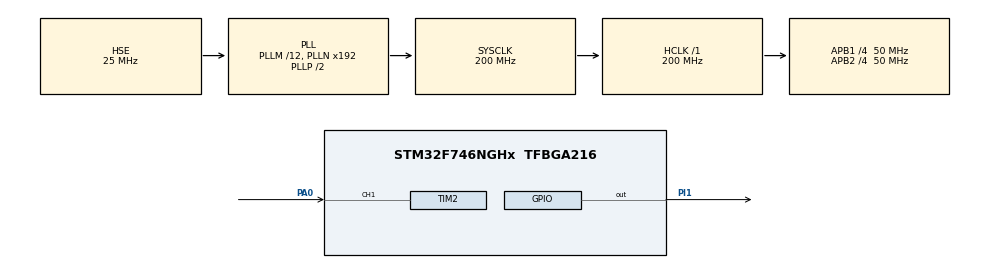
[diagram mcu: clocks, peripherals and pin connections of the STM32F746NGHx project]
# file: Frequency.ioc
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Mcu.Family=STM32F7
Mcu.Name=STM32F746NGHx
Mcu.Package=TFBGA216
NVIC.PVD_IRQn=true\:0\:0\:false\:false\:true\:true\:true
NVIC.PriorityGroup=NVIC_PRIORITYGROUP_4
NVIC.TIM2_IRQn=true\:0\:0\:false\:false\:true\:true\:true
PA0/WKUP.Signal=S_TIM2_CH1_ETR
PA13.Mode=Serial_Wire
PA13.Signal=SYS_JTMS-SWDIO
PA14.Mode=Serial_Wire
PA14.Signal=SYS_JTCK-SWCLK
PC14/OSC32_IN.Mode=LSE-External-Oscillator
PC14/OSC32_IN.Signal=RCC_OSC32_IN
PC15/OSC32_OUT.Mode=LSE-External-Oscillator
PC15/OSC32_OUT.Signal=RCC_OSC32_OUT
PH0/OSC_IN.Mode=HSE-External-Oscillator
PH0/OSC_IN.Signal=RCC_OSC_IN
PH1/OSC_OUT.Mode=HSE-External-Oscillator
PH1/OSC_OUT.Signal=RCC_OSC_OUT
PI1.Signal=GPIO_Output
ProjectManager.HeapSize=0x200
ProjectManager.StackSize=0x400
ProjectManager.TargetToolchain=STM32CubeIDE
RCC.AHBFreq_Value=200000000
RCC.APB1CLKDivider=RCC_HCLK_DIV4
RCC.APB1Freq_Value=50000000
RCC.APB1TimFreq_Value=100000000
RCC.APB2CLKDivider=RCC_HCLK_DIV4
RCC.APB2Freq_Value=50000000
RCC.APB2TimFreq_Value=100000000
RCC.CortexFreq_Value=200000000
RCC.HCLKFreq_Value=200000000
RCC.HSE_VALUE=25000000
RCC.HSI_VALUE=16000000
RCC.PLL48CLockSelection=RCC_CLK48SOURCE_PLLSAIP
RCC.PLLI2SN=100
RCC.PLLM=12
RCC.PLLQ=9
RCC.PLLSAIN=384
RCC.PLLSAIP=RCC_PLLSAIP_DIV8
RCC.PLLSAIR=5
RCC.PLLSAIRDiv=RCC_PLLSAIDIVR_8
RCC.PLLSourceVirtual=RCC_PLLSOURCE_HSE
RCC.SDMMCClockSelection=RCC_SDMMC1CLKSOURCE_CLK48
RCC.SYSCLKFreq_VALUE=200000000
RCC.SYSCLKSource=RCC_SYSCLKSOURCE_PLLCLK
RCC.USBFreq_Value=100000000
RCC.VCOOutputFreq_Value=400000000
SH.S_TIM2_CH1_ETR.0=TIM2_CH1,Input_Capture1_from_TI1
TIM2.Channel-Input_Capture1_from_TI1=TIM_CHANNEL_1
TIM2.ICFilter_CH1=15
TIM2.ICPrescaler-Input_Capture1_from_TI1=TIM_ICPSC_DIV1
TIM2.Prescaler=10-1
VP_CRC_VS_CRC.Mode=CRC_Activate
VP_DMA2D_VS_DMA2D.Mode=DMA2D_Activate
VP_RTC_VS_RTC_Activate.Mode=RTC_Enabled
board=STM32F746G-DISCO

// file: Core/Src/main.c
/* USER CODE BEGIN Header */
/**
  ******************************************************************************
  * @file           : main.c
  * @brief          : Main program body
  ******************************************************************************
  * @attention
  *
  * <h2><center>&copy; Copyright (c) 2021 STMicroelectronics.
  * All rights reserved.</center></h2>
  *
  * This software component is licensed by ST under Ultimate Liberty license
  * SLA0044, the "License"; You may not use this file except in compliance with
  * the License. You may obtain a copy of the License at:
  *                             www.st.com/SLA0044
  *
  ******************************************************************************
  */
/* USER CODE END Header */
#include "main.h"

CRC_HandleTypeDef hcrc;

DMA2D_HandleTypeDef hdma2d;

RTC_HandleTypeDef hrtc;

TIM_HandleTypeDef htim2;

/* USER CODE BEGIN PV */
float IC_Value1 = 0;
float IC_Value2 = 0;
float Difference = 0;
float Frequency = 0;
uint8_t Is_First_Captured = 0;

uint8_t counter_1_1;
uint8_t counter_1_2;
uint8_t counter_1_3;
uint8_t counter_1_4;

uint32_t counter1value_int=0;

//uint32_t counter;
uint32_t read;

uint32_t fr_apb1 = 0;

/* USER CODE END PV */

void SystemClock_Config(void);
static void MX_GPIO_Init(void);
static void MX_TIM2_Init(void);
static void MX_RTC_Init(void);
static void MX_CRC_Init(void);
static void MX_DMA2D_Init(void);

/* USER CODE BEGIN 0 */

TS_StateTypeDef  ts;

char tCounter[20];
char xTouchStr[10];
char freq[10];

/* USER CODE END 0 */

int main(void)
{

  /* MCU Configuration--------------------------------------------------------*/

  /* Reset of all peripherals, Initializes the Flash interface and the Systick. */
  HAL_Init();

  /* Configure the system clock */
  SystemClock_Config();

  /* Initialize all configured peripherals */
  MX_GPIO_Init();
  MX_TIM2_Init();
  MX_RTC_Init();
  MX_CRC_Init();
  MX_DMA2D_Init();
  /* USER CODE BEGIN 2 */

  HAL_TIM_IC_Start_IT(&htim2, TIM_CHANNEL_1);

  HAL_Delay(100);

  BSP_SDRAM_Init(); /* Initializes the SDRAM device */

  BSP_TS_Init(480, 272);
  BSP_LCD_Init();
  BSP_LCD_LayerDefaultInit(0, LCD_FB_START_ADDRESS);
  BSP_LCD_DisplayOn();
  BSP_LCD_SelectLayer(0);
  BSP_LCD_Clear(LCD_COLOR_BLUE);

  HAL_Delay(1000);

  /* USER CODE END 2 */

  /* Infinite loop */
  /* USER CODE BEGIN WHILE */
  while (1)
  {
	  BSP_TS_GetState(&ts);

    /* USER CODE END WHILE */

    /* USER CODE BEGIN 3 */

	sprintf(freq, "Frequency: %5.1f",Frequency);

    BSP_LCD_DisplayStringAt(100, 130, (float *)freq, LEFT_MODE);

    HAL_Delay(1000);

  }
  /* USER CODE END 3 */
}

void SystemClock_Config(void)
{
  RCC_OscInitTypeDef RCC_OscInitStruct = {0};
  RCC_ClkInitTypeDef RCC_ClkInitStruct = {0};
  RCC_PeriphCLKInitTypeDef PeriphClkInitStruct = {0};

  /** Configure LSE Drive Capability
  */
  HAL_PWR_EnableBkUpAccess();
  /** Configure the main internal regulator output voltage
  */
  __HAL_RCC_PWR_CLK_ENABLE();
  __HAL_PWR_VOLTAGESCALING_CONFIG(PWR_REGULATOR_VOLTAGE_SCALE1);
  /** Initializes the RCC Oscillators according to the specified parameters
  * in the RCC_OscInitTypeDef structure.
  */
  RCC_OscInitStruct.OscillatorType = RCC_OSCILLATORTYPE_LSI|RCC_OSCILLATORTYPE_HSE;
  RCC_OscInitStruct.HSEState = RCC_HSE_ON;
  RCC_OscInitStruct.LSIState = RCC_LSI_ON;
  RCC_OscInitStruct.PLL.PLLState = RCC_PLL_ON;
  RCC_OscInitStruct.PLL.PLLSource = RCC_PLLSOURCE_HSE;
  RCC_OscInitStruct.PLL.PLLM = 12;
  RCC_OscInitStruct.PLL.PLLN = 192;
  RCC_OscInitStruct.PLL.PLLP = RCC_PLLP_DIV2;
  RCC_OscInitStruct.PLL.PLLQ = 9;
  if (HAL_RCC_OscConfig(&RCC_OscInitStruct) != HAL_OK)
  {
    Error_Handler();
  }
  /** Activate the Over-Drive mode
  */
  if (HAL_PWREx_EnableOverDrive() != HAL_OK)
  {
    Error_Handler();
  }
  /** Initializes the CPU, AHB and APB buses clocks
  */
  RCC_ClkInitStruct.ClockType = RCC_CLOCKTYPE_HCLK|RCC_CLOCKTYPE_SYSCLK
                              |RCC_CLOCKTYPE_PCLK1|RCC_CLOCKTYPE_PCLK2;
  RCC_ClkInitStruct.SYSCLKSource = RCC_SYSCLKSOURCE_PLLCLK;
  RCC_ClkInitStruct.AHBCLKDivider = RCC_SYSCLK_DIV1;
  RCC_ClkInitStruct.APB1CLKDivider = RCC_HCLK_DIV4;
  RCC_ClkInitStruct.APB2CLKDivider = RCC_HCLK_DIV4;

  if (HAL_RCC_ClockConfig(&RCC_ClkInitStruct, FLASH_LATENCY_6) != HAL_OK)
  {
    Error_Handler();
  }
  PeriphClkInitStruct.PeriphClockSelection = RCC_PERIPHCLK_RTC;
  PeriphClkInitStruct.RTCClockSelection = RCC_RTCCLKSOURCE_LSI;
  if (HAL_RCCEx_PeriphCLKConfig(&PeriphClkInitStruct) != HAL_OK)
  {
    Error_Handler();
  }
}

static void MX_CRC_Init(void)
{

  hcrc.Instance = CRC;
  hcrc.Init.DefaultPolynomialUse = DEFAULT_POLYNOMIAL_ENABLE;
  hcrc.Init.DefaultInitValueUse = DEFAULT_INIT_VALUE_ENABLE;
  hcrc.Init.InputDataInversionMode = CRC_INPUTDATA_INVERSION_NONE;
  hcrc.Init.OutputDataInversionMode = CRC_OUTPUTDATA_INVERSION_DISABLE;
  hcrc.InputDataFormat = CRC_INPUTDATA_FORMAT_BYTES;
  if (HAL_CRC_Init(&hcrc) != HAL_OK)
  {
    Error_Handler();
  }

}

static void MX_DMA2D_Init(void)
{

  hdma2d.Instance = DMA2D;
  hdma2d.Init.Mode = DMA2D_M2M;
  hdma2d.Init.ColorMode = DMA2D_OUTPUT_ARGB8888;
  hdma2d.Init.OutputOffset = 0;
  hdma2d.LayerCfg[1].InputOffset = 0;
  hdma2d.LayerCfg[1].InputColorMode = DMA2D_INPUT_ARGB8888;
  hdma2d.LayerCfg[1].AlphaMode = DMA2D_NO_MODIF_ALPHA;
  hdma2d.LayerCfg[1].InputAlpha = 0;
  if (HAL_DMA2D_Init(&hdma2d) != HAL_OK)
  {
    Error_Handler();
  }
  if (HAL_DMA2D_ConfigLayer(&hdma2d, 1) != HAL_OK)
  {
    Error_Handler();
  }

}

static void MX_RTC_Init(void)
{

  /** Initialize RTC Only
  */
  hrtc.Instance = RTC;
  hrtc.Init.HourFormat = RTC_HOURFORMAT_24;
  hrtc.Init.AsynchPrediv = 127;
  hrtc.Init.SynchPrediv = 255;
  hrtc.Init.OutPut = RTC_OUTPUT_DISABLE;
  hrtc.Init.OutPutPolarity = RTC_OUTPUT_POLARITY_HIGH;
  hrtc.Init.OutPutType = RTC_OUTPUT_TYPE_OPENDRAIN;
  if (HAL_RTC_Init(&hrtc) != HAL_OK)
  {
    Error_Handler();
  }

}

static void MX_TIM2_Init(void)
{

  TIM_MasterConfigTypeDef sMasterConfig = {0};
  TIM_IC_InitTypeDef sConfigIC = {0};

  htim2.Instance = TIM2;
  htim2.Init.Prescaler = 10-1;
  htim2.Init.CounterMode = TIM_COUNTERMODE_UP;
  htim2.Init.Period = 4294967295;
  htim2.Init.ClockDivision = TIM_CLOCKDIVISION_DIV1;
  htim2.Init.AutoReloadPreload = TIM_AUTORELOAD_PRELOAD_DISABLE;
  if (HAL_TIM_IC_Init(&htim2) != HAL_OK)
  {
    Error_Handler();
  }
  sMasterConfig.MasterOutputTrigger = TIM_TRGO_RESET;
  sMasterConfig.MasterSlaveMode = TIM_MASTERSLAVEMODE_DISABLE;
  if (HAL_TIMEx_MasterConfigSynchronization(&htim2, &sMasterConfig) != HAL_OK)
  {
    Error_Handler();
  }
  sConfigIC.ICPolarity = TIM_INPUTCHANNELPOLARITY_RISING;
  sConfigIC.ICSelection = TIM_ICSELECTION_DIRECTTI;
  sConfigIC.ICPrescaler = TIM_ICPSC_DIV1;
  sConfigIC.ICFilter = 15;
  if (HAL_TIM_IC_ConfigChannel(&htim2, &sConfigIC, TIM_CHANNEL_1) != HAL_OK)
  {
    Error_Handler();
  }

}

static void MX_GPIO_Init(void)
{
  GPIO_InitTypeDef GPIO_InitStruct = {0};

  /* GPIO Ports Clock Enable */
  __HAL_RCC_GPIOA_CLK_ENABLE();
  __HAL_RCC_GPIOI_CLK_ENABLE();
  __HAL_RCC_GPIOC_CLK_ENABLE();
  __HAL_RCC_GPIOH_CLK_ENABLE();

  /*Configure GPIO pin Output Level */
  HAL_GPIO_WritePin(GPIOI, GPIO_PIN_1, GPIO_PIN_RESET);

  /*Configure GPIO pin : PI1 */
  GPIO_InitStruct.Pin = GPIO_PIN_1;
  GPIO_InitStruct.Mode = GPIO_MODE_OUTPUT_PP;
  GPIO_InitStruct.Pull = GPIO_NOPULL;
  GPIO_InitStruct.Speed = GPIO_SPEED_FREQ_LOW;
  HAL_GPIO_Init(GPIOI, &GPIO_InitStruct);

}

/* USER CODE BEGIN 4 */

void HAL_TIM_IC_CaptureCallback(TIM_HandleTypeDef *htim)
{
	if (htim->Channel == HAL_TIM_ACTIVE_CHANNEL_1)  // if interrput source is channel 1
	{
		if (Is_First_Captured==0)  // is the first value captured ?
		{
			IC_Value1 = HAL_TIM_ReadCapturedValue(htim, TIM_CHANNEL_1);  // capture the first value
			Is_First_Captured =1;  // set the first value captured as true
		}

		else if (Is_First_Captured)  // if the first is captured
		{
			IC_Value2 = HAL_TIM_ReadCapturedValue(htim, TIM_CHANNEL_1);  // capture second value

			if (IC_Value2 > IC_Value1)
			{
				Difference = IC_Value2-IC_Value1;   // calculate the difference
			}

			else if (IC_Value2 < IC_Value1)
			{
				Difference = ((0xffff-IC_Value1)+IC_Value2) +1;
			}

			else
			{
				Error_Handler();
			}

		//	Frequency = HAL_RCC_GetPCLK1Freq();
			Frequency = (HAL_RCC_GetPCLK1Freq()*2)/Difference;  // calculate frequency

			Frequency = Frequency/10.0;

			Is_First_Captured = 0;  // reset the first captured

		}
	}
}

/* USER CODE END 4 */

void Error_Handler(void)
{
  __disable_irq();
  while (1)
  {
  }
}

/************************ (C) COPYRIGHT STMicroelectronics *****END OF FILE****/
